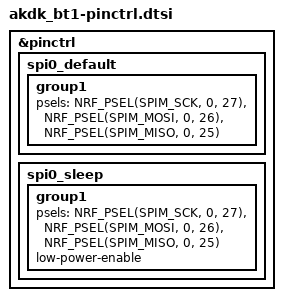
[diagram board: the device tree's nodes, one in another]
/*
 * Copyright (c) 2023, ZMK Contributors
 * SPDX-License-Identifier: MIT
 */

&pinctrl {
    spi0_default: spi0_default {
        group1 {
            psels = <NRF_PSEL(SPIM_SCK, 0, 27)>,
                   <NRF_PSEL(SPIM_MOSI, 0, 26)>,
                   <NRF_PSEL(SPIM_MISO, 0, 25)>;
        };
    };

    spi0_sleep: spi0_sleep {
        group1 {
            psels = <NRF_PSEL(SPIM_SCK, 0, 27)>,
                   <NRF_PSEL(SPIM_MOSI, 0, 26)>,
                   <NRF_PSEL(SPIM_MISO, 0, 25)>;
            low-power-enable;
        };
    };
}; 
